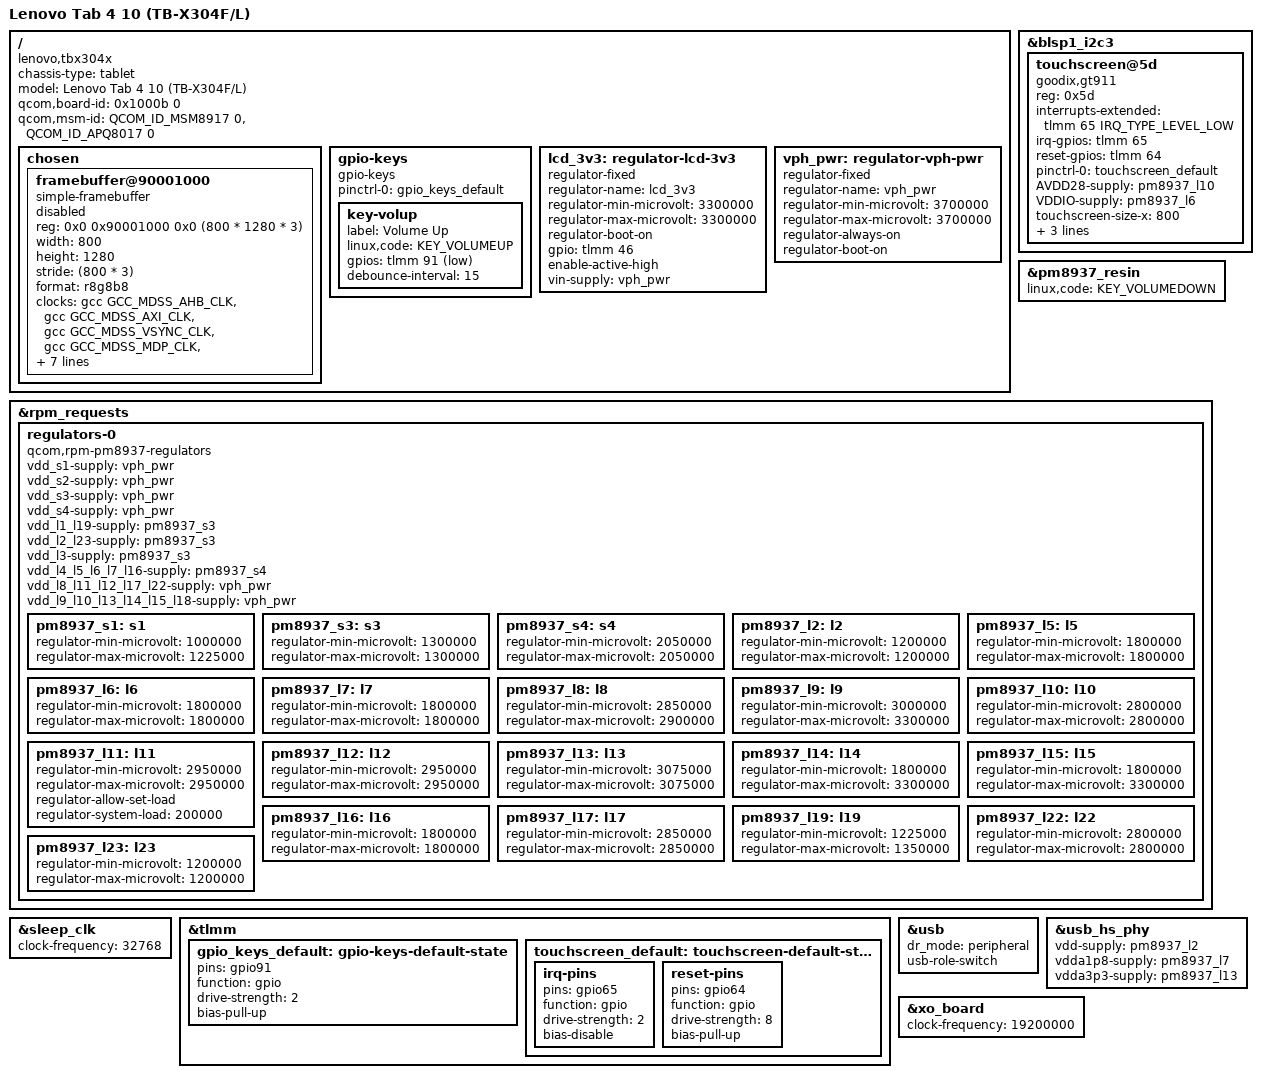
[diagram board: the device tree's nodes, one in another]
// SPDX-License-Identifier: GPL-2.0
/dts-v1/;
#include <dt-bindings/arm/qcom,ids.h>
#include <dt-bindings/gpio/gpio.h>
#include "msm8917.dtsi"
#include "pm8937.dtsi"

/ {
	chassis-type = "tablet";
	compatible = "lenovo,tbx304x", "qcom,msm8917";
	model = "Lenovo Tab 4 10 (TB-X304F/L)";
	qcom,board-id = <0x1000b 0>;
	qcom,msm-id = <QCOM_ID_MSM8917 0>, <QCOM_ID_APQ8017 0>;

	chosen {
		#address-cells = <2>;
		#size-cells = <2>;
		ranges;

		/* The bootloader fills in and enables the framebuffer. */
		framebuffer@90001000 {
			compatible = "simple-framebuffer";
			reg = <0x0 0x90001000 0x0 (800 * 1280 * 3)>;
			width = <800>;
			height = <1280>;
			stride = <(800 * 3)>;
			format = "r8g8b8";
			clocks = <&gcc GCC_MDSS_AHB_CLK>,
				 <&gcc GCC_MDSS_AXI_CLK>,
				 <&gcc GCC_MDSS_VSYNC_CLK>,
				 <&gcc GCC_MDSS_MDP_CLK>,
				 <&gcc GCC_MDSS_BYTE0_CLK>,
				 <&gcc GCC_MDSS_PCLK0_CLK>,
				 <&gcc GCC_MDSS_ESC0_CLK>;
			power-domains = <&gcc MDSS_GDSC>;
			lcd-supply = <&lcd_3v3>;
			vdda-supply = <&pm8937_l2>;
			vddio-supply = <&pm8937_l6>;

			status = "disabled";
		};
	};

	gpio-keys {
		compatible = "gpio-keys";

		pinctrl-0 = <&gpio_keys_default>;
		pinctrl-names = "default";

		key-volup {
			label = "Volume Up";
			linux,code = <KEY_VOLUMEUP>;
			gpios = <&tlmm 91 GPIO_ACTIVE_LOW>;
			debounce-interval = <15>;
		};
	};

	lcd_3v3: regulator-lcd-3v3 {
		compatible = "regulator-fixed";
		regulator-name = "lcd_3v3";
		regulator-min-microvolt = <3300000>;
		regulator-max-microvolt = <3300000>;
		regulator-boot-on;
		gpio = <&tlmm 46 GPIO_ACTIVE_HIGH>;
		enable-active-high;
		vin-supply = <&vph_pwr>;
	};

	vph_pwr: regulator-vph-pwr {
		compatible = "regulator-fixed";
		regulator-name = "vph_pwr";
		regulator-min-microvolt = <3700000>;
		regulator-max-microvolt = <3700000>;
		regulator-always-on;
		regulator-boot-on;
	};
};

&blsp1_i2c3 {
	status = "okay";

	touchscreen@5d {
		compatible = "goodix,gt911";
		reg = <0x5d>;
		interrupts-extended = <&tlmm 65 IRQ_TYPE_LEVEL_LOW>;
		irq-gpios = <&tlmm 65 GPIO_ACTIVE_HIGH>;
		reset-gpios = <&tlmm 64 GPIO_ACTIVE_HIGH>;
		pinctrl-0 = <&touchscreen_default>;
		pinctrl-names = "default";
		AVDD28-supply = <&pm8937_l10>;
		VDDIO-supply = <&pm8937_l6>;
		touchscreen-size-x = <800>;
		touchscreen-size-y = <1280>;
		touchscreen-inverted-x;
		touchscreen-inverted-y;
	};
};

&pm8937_resin {
	linux,code = <KEY_VOLUMEDOWN>;

	status = "okay";
};

&rpm_requests {
	regulators-0 {
		compatible = "qcom,rpm-pm8937-regulators";

		vdd_s1-supply = <&vph_pwr>;
		vdd_s2-supply = <&vph_pwr>;
		vdd_s3-supply = <&vph_pwr>;
		vdd_s4-supply = <&vph_pwr>;
		vdd_l1_l19-supply = <&pm8937_s3>;
		vdd_l2_l23-supply = <&pm8937_s3>;
		vdd_l3-supply = <&pm8937_s3>;
		vdd_l4_l5_l6_l7_l16-supply = <&pm8937_s4>;
		vdd_l8_l11_l12_l17_l22-supply = <&vph_pwr>;
		vdd_l9_l10_l13_l14_l15_l18-supply = <&vph_pwr>;

		pm8937_s1: s1 {
			regulator-min-microvolt = <1000000>;
			regulator-max-microvolt = <1225000>;
		};

		pm8937_s3: s3 {
			regulator-min-microvolt = <1300000>;
			regulator-max-microvolt = <1300000>;
		};

		pm8937_s4: s4 {
			regulator-min-microvolt = <2050000>;
			regulator-max-microvolt = <2050000>;
		};

		pm8937_l2: l2 {
			regulator-min-microvolt = <1200000>;
			regulator-max-microvolt = <1200000>;
		};

		pm8937_l5: l5 {
			regulator-min-microvolt = <1800000>;
			regulator-max-microvolt = <1800000>;
		};

		pm8937_l6: l6 {
			regulator-min-microvolt = <1800000>;
			regulator-max-microvolt = <1800000>;
		};

		pm8937_l7: l7 {
			regulator-min-microvolt = <1800000>;
			regulator-max-microvolt = <1800000>;
		};

		pm8937_l8: l8 {
			regulator-min-microvolt = <2850000>;
			regulator-max-microvolt = <2900000>;
		};

		pm8937_l9: l9 {
			regulator-min-microvolt = <3000000>;
			regulator-max-microvolt = <3300000>;
		};

		pm8937_l10: l10 {
			regulator-min-microvolt = <2800000>;
			regulator-max-microvolt = <2800000>;
		};

		pm8937_l11: l11 {
			regulator-min-microvolt = <2950000>;
			regulator-max-microvolt = <2950000>;
			regulator-allow-set-load;
			regulator-system-load = <200000>;
		};

		pm8937_l12: l12 {
			regulator-min-microvolt = <2950000>;
			regulator-max-microvolt = <2950000>;
		};

		pm8937_l13: l13 {
			regulator-min-microvolt = <3075000>;
			regulator-max-microvolt = <3075000>;
		};

		pm8937_l14: l14 {
			regulator-min-microvolt = <1800000>;
			regulator-max-microvolt = <3300000>;
		};

		pm8937_l15: l15 {
			regulator-min-microvolt = <1800000>;
			regulator-max-microvolt = <3300000>;
		};

		pm8937_l16: l16 {
			regulator-min-microvolt = <1800000>;
			regulator-max-microvolt = <1800000>;
		};

		pm8937_l17: l17 {
			regulator-min-microvolt = <2850000>;
			regulator-max-microvolt = <2850000>;
		};

		pm8937_l19: l19 {
			regulator-min-microvolt = <1225000>;
			regulator-max-microvolt = <1350000>;
		};

		pm8937_l22: l22 {
			regulator-min-microvolt = <2800000>;
			regulator-max-microvolt = <2800000>;
		};

		pm8937_l23: l23 {
			regulator-min-microvolt = <1200000>;
			regulator-max-microvolt = <1200000>;
		};
	};
};

&sleep_clk {
	clock-frequency = <32768>;
};

&tlmm {
	gpio_keys_default: gpio-keys-default-state {
		pins = "gpio91";
		function = "gpio";
		drive-strength = <2>;
		bias-pull-up;
	};

	touchscreen_default: touchscreen-default-state {
		irq-pins {
			pins = "gpio65";
			function = "gpio";
			drive-strength = <2>;
			bias-disable;
		};

		reset-pins {
			pins = "gpio64";
			function = "gpio";
			drive-strength = <8>;
			bias-pull-up;
		};
	};
};

&usb {
	dr_mode = "peripheral";
	usb-role-switch;
	status = "okay";
};

&usb_hs_phy {
	vdd-supply = <&pm8937_l2>;
	vdda1p8-supply = <&pm8937_l7>;
	vdda3p3-supply = <&pm8937_l13>;

	status = "okay";
};

&xo_board {
	clock-frequency = <19200000>;
};
